# CH32F103xx register map
Vendor: WCH Ltd.; File version: 1.0
CH32F103xx View File
Registers are 32-bit, read-write, reset 0x0 unless marked. A register's access mark holds for its fields unless they carry their own. Offsets are from the block's base; lines under a group give offsets from that group; [hi:lo] are bit positions; {n}, {i} and the like mark numbered series; 'fields as' and 'values as' point back to an identical list; <NAME> marks a mode.

## Memory map
0x40000000 TIM2 size 0x400 — General purpose timer
0x40000400 TIM3 size 0x400
0x40000800 TIM4 size 0x400
0x40002800 RTC size 0x400 — Real time clock
0x40002C00 WWDG size 0x400 — Window watchdog
0x40003000 IWDG size 0x400 — Independent watchdog
0x40003800 SPI2 size 0x400
0x40004400 USART2 size 0x400
0x40004800 USART3 size 0x400
0x40005400 I2C1 size 0x400 — Inter integrated circuit
0x40005800 I2C2 size 0x400
0x40005C00 USBD size 0x400 — Universal serial bus full-speed device interface
0x40006400 CAN size 0x400 — Controller area network
0x40006C00 BKP size 0x400 — Backup registers
0x40007000 PWR size 0x400 — Power control
0x40007400 DAC1 size 0x400 — Digital to analog converter
0x40008000 USBHD size 0x400 — USB register
0x40010000 AFIO size 0x400 — Alternate function I/O
0x40010400 EXTI size 0x400
0x40010800 GPIOA size 0x400 — General purpose I/O
0x40010C00 GPIOB size 0x400
0x40011000 GPIOC size 0x400
0x40011400 GPIOD size 0x400
0x40012400 ADC1 size 0x400 — Analog to digital converter
0x40012800 ADC2 size 0x400 — Analog to digital converter
0x40012C00 TIM1 size 0x400 — Advanced timer
0x40013000 SPI1 size 0x400 — Serial peripheral interface
0x40013800 USART1 size 0x400 — Universal synchronous asynchronous receiver transmitter
0x40020000 DMA size 0x400 — DMA controller
0x40021000 RCC size 0x400 — Reset and clock control
0x40022000 FLASH size 0x400
0x40023000 CRC size 0x400 — CRC calculation unit
0xE000E000 PFIC size 0x1100 — Programmable Fast Interrupt Controller
0xE0042000 DBG size 0x400 — Debug support

## Interrupts
0 WWDG — Window Watchdog interrupt
1 PVD (PWR) — PVD through EXTI line detection interrupt
2 TAMPER (EXTI) — Tamper interrupt
3 RTC — RTC global interrupt
4 FLASH — Flash global interrupt
5 RCC — RCC global interrupt
6 EXTI0 (EXTI) — EXTI Line0 interrupt
7 EXTI1 (EXTI) — EXTI Line1 interrupt
8 EXTI2 (EXTI) — EXTI Line2 interrupt
9 EXTI3 (EXTI) — EXTI Line3 interrupt
10 EXTI4 (EXTI) — EXTI Line4 interrupt
11 DMA1_Channel1 (DMA) — DMA1 Channel1 global interrupt
12 DMA1_Channel2 (DMA) — DMA1 Channel2 global interrupt
13 DMA1_Channel3 (DMA) — DMA1 Channel3 global interrupt
14 DMA1_Channel4 (DMA) — DMA1 Channel4 global interrupt
15 DMA1_Channel5 (DMA) — DMA1 Channel5 global interrupt
16 DMA1_Channel6 (DMA) — DMA1 Channel6 global interrupt
17 DMA1_Channel7 (DMA) — DMA1 Channel7 global interrupt
18 ADC (ADC1) — ADC1 global interrupt
19 CAN1_TX (CAN) — CAN1 TX interrupts
20 CAN1_RX0 (CAN) — CAN1 RX0 interrupts
21 CAN1_RX1 (CAN) — CAN1 RX1 interrupt
22 CAN1_SCE (CAN) — CAN1 SCE interrupt
23 EXTI9_5 (EXTI) — EXTI Line[9:5] interrupts
24 TIM1_BRK_TIM9 (TIM1) — TIM1 Break interrupt and TIM9 global interrupt
25 TIM1_UP_TIM10 (TIM1) — TIM1 Update interrupt and TIM10 global interrupt
26 TIM1_TRG_COM_TIM11 (TIM1) — TIM1 Trigger and Commutation interrupts and TIM11 global interrupt
27 TIM1_CC (TIM1) — TIM1 Capture Compare interrupt
28 TIM2 — TIM2 global interrupt
29 TIM3 — TIM3 global interrupt
30 TIM4 — TIM4 global interrupt
31 I2C1_EV (I2C1) — I2C1 event interrupt
32 I2C1_ER (I2C1) — I2C1 error interrupt
33 I2C2_EV (I2C2) — I2C2 event interrupt
34 I2C2_ER (I2C2) — I2C2 error interrupt
35 SPI1 — SPI1 global interrupt
36 SPI2 — SPI2 global interrupt
37 USART1 — USART1 global interrupt
38 USART2 — USART2 global interrupt
39 USART3 — USART3 global interrupt
40 EXTI15_10 (EXTI) — EXTI Line[15:10] interrupts
41 RTCAlarm (RTC) — RTC Alarms through EXTI line interrupt
42 USB_FS_WKUP (USBD) — USB Device FS Wakeup through EXTI line interrupt
43 USBHD — USBHD_IRQHandler

## PWR — Power control
Base 0x40007000
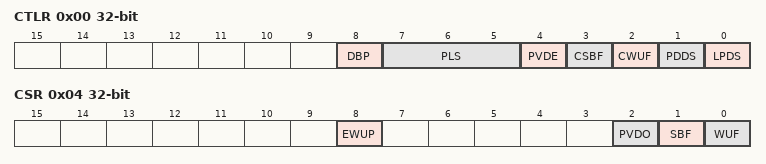
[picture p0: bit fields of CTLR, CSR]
0x00 CTLR — Power control register (PWR_CTRL)
  [8] DBP — Disable Backup Domain write protection
  [7:5] PLS — PVD Level Selection
  [4] PVDE — Power Voltage Detector Enable
  [3] CSBF — Clear STANDBY Flag
  [2] CWUF — Clear Wake-up Flag
  [1] PDDS — Power Down Deep Sleep
  [0] LPDS — Low Power Deep Sleep
0x04 CSR access per field — Power control register (PWR_CSR)
  [8] EWUP rw — Enable WKUP pin
  [2] PVDO ro — PVD Output
  [1] SBF ro — STANDBY Flag
  [0] WUF ro — Wake-Up Flag
